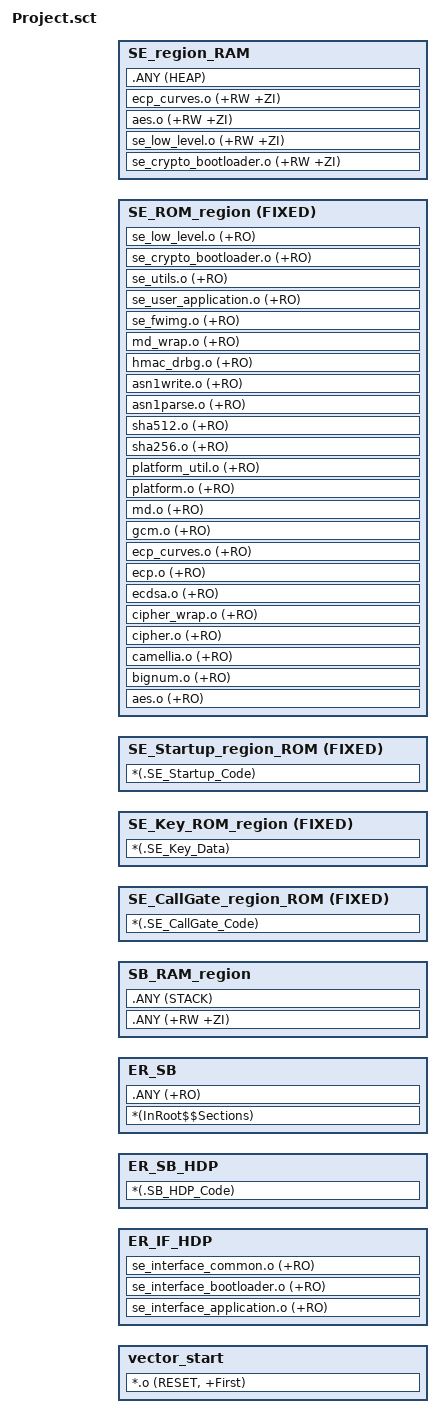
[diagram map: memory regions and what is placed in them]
#! armclang --target=arm-arm-none-eabi  -mcpu=cortex-m4 -E -xc
; *************************************************************
; *** Scatter-Loading Description File generated by uVision ***
; *************************************************************
#include "..\..\Linker_Common\KEIL\mapping_sbsfu.h"
#include "..\..\Linker_Common\KEIL\mapping_fwimg.h"

; *** regions needed by SBSFU project ***
LR_ROM_Vector ROM_START VECTOR_SIZE {
  vector_start ROM_START VECTOR_SIZE {
  *.o (RESET, +First)
  }
}

LR_IF SE_IF_REGION_ROM_START SE_IF_ROM_REGION_SIZE {
  ER_IF_HDP SE_IF_REGION_ROM_START SE_IF_ROM_REGION_SIZE {
     se_interface_application.o (+RO)
	 se_interface_bootloader.o (+RO)
	 se_interface_common.o (+RO)
  }
}

LR_SB_HDP SB_HDP_REGION_ROM_START SB_HDP_ROM_REGION_SIZE {
  ER_SB_HDP SB_HDP_CODE_REGION_RAM_START SB_HDP_CODE_RAM_REGION_SIZE {
  *(.SB_HDP_Code)
  }
}

LR_SB SB_REGION_ROM_START SB_ROM_REGION_SIZE {  
  ER_SB SB_REGION_ROM_START SB_ROM_REGION_SIZE {
  *(InRoot$$Sections)
  .ANY (+RO)
  }
  SB_RAM_region SB_REGION_RAM_START SB_RAM_REGION_SIZE  {
  .ANY (+RW +ZI)
  .ANY (STACK)  
  }
}
LR_SE_Entry_Secure_ROM_Region SE_CODE_REGION_ROM_START {
  SE_CallGate_region_ROM SE_CALLGATE_REGION_ROM_START FIXED SE_CALLGATE_REGION_ROM_SIZE {
  *(.SE_CallGate_Code)
  }
  SE_Key_ROM_region SE_KEY_REGION_ROM_START FIXED SE_KEY_REGION_ROM_SIZE {
  *(.SE_Key_Data)
  }
  SE_Startup_region_ROM SE_STARTUP_REGION_ROM_START FIXED  {
  *(.SE_Startup_Code)
  }
  SE_ROM_region SE_CODE_NOKEY_REGION_ROM_START FIXED SE_ROM_REGION_SIZE { 
  aes.o (+RO)
  bignum.o (+RO)
  camellia.o (+RO)
  cipher.o (+RO)
  cipher_wrap.o (+RO)
  ecdsa.o (+RO)
  ecp.o (+RO)
  ecp_curves.o (+RO)
  gcm.o (+RO)
  md.o (+RO)
  platform.o (+RO)
  platform_util.o (+RO)
  sha256.o (+RO)
  sha512.o (+RO)
  asn1parse.o (+RO)
  asn1write.o (+RO)
  hmac_drbg.o (+RO)  
  md_wrap.o (+RO)  
  se_fwimg.o (+RO)
  se_user_application.o (+RO)
  se_utils.o (+RO)
  se_crypto_bootloader.o (+RO)
  se_low_level.o (+RO)
  } 
  SE_region_RAM SE_REGION_RAM_STACK_TOP SE_RAM_REGION_SIZE  {  
  se_crypto_bootloader.o (+RW +ZI) 
  se_low_level.o (+RW +ZI)   
  aes.o (+RW +ZI)
  ecp_curves.o (+RW +ZI)
  .ANY (HEAP)
  }  
}

